# SF32LB55x register map
File version: 1.0
CPU: CM33 r0p1, little endian, MPU, FPU, 3 interrupt priority bits
Registers are 32-bit, read-write, reset 0x0 unless marked. A register's access mark holds for its fields unless they carry their own. Offsets are from the block's base; [hi:lo] are bit positions; {n}, {i} and the like mark numbered series.

## PMUC
Base 0x4007A000
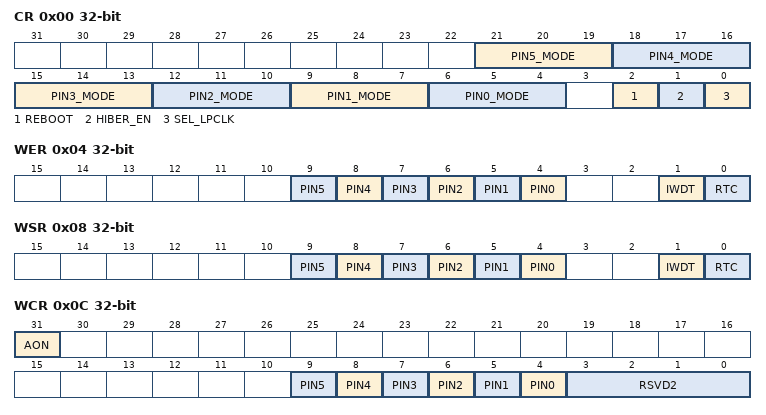
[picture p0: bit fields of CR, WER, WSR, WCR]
0x00 CR — Control Register
  [3n+6:3n+4] PIN{n}_MODE (n=1..5)
  [6:4] PIN0_MODE — 0 - high level, 1 - low level, 2 - pos edge, 3 - neg edge, 4/5/6/7: pos or neg edge
  [2] REBOOT — Write 1 to reboot; write 0 to clear after boot up
  [1] HIBER_EN — Write 1 to enter hibernate mode; write 0 to clear when exit from hibernate
  [0] SEL_LPCLK — 0 - LRC10, 1 - LXT32
0x04 WER — Wakeup Enable register
  [n+4] PIN{n} (n=0..5)
  [1] IWDT — Set 1 to enable IWDT as wakeup source
  [0] RTC — Set 1 to enable RTC as wakeup source
0x08 WSR — Wakeup Status register
  [n+4] PIN{n} (n=0..5)
  [1] IWDT — Indicates the wakeup status from LPTIM2. Note: the status is masked by WER
  [0] RTC — Indicates the wakeup status from RTC. Note: the status is masked by WER
0x0C WCR — Wakeup Clear register
  [31] AON — Write 1 to clear the AON wakeup IRQ status
  [n+4] PIN{n} (n=1..5)
  [4] PIN0 — Write 1 to clear the PIN0 wakeup source. Only valid if PIN wakeup is configured as edge trigger
  [3:0] RSVD2 — Note: for LPTIM and LPUART, clear the wakeup status directly in the orignal module
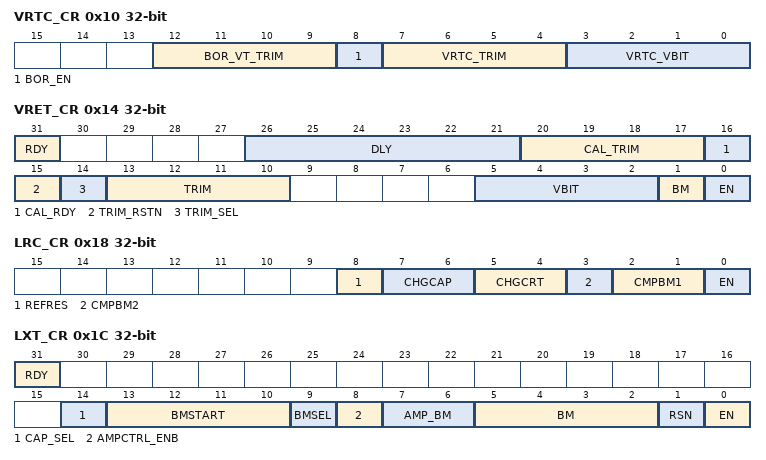
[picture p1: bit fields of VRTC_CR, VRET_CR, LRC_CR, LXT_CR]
0x10 VRTC_CR — VRTC Control Register
  [12:9] BOR_VT_TRIM
  [8] BOR_EN — Brownout Reset Enable
  [7:4] VRTC_TRIM
  [3:0] VRTC_VBIT
0x14 VRET_CR — VRET Control Register
  [31] RDY
  [26:21] DLY — VRET_LDO power up delay in number of CLK_LP cycles
  [20:17] CAL_TRIM
  [16] CAL_RDY
  [15] TRIM_RSTN
  [14] TRIM_SEL
  [13:10] TRIM
  [5:2] VBIT
  [1] BM
  [0] EN
0x18 LRC_CR — RC10K Control Register
  [8] REFRES
  [7:6] CHGCAP
  [5:4] CHGCRT
  [3] CMPBM2
  [2:1] CMPBM1
  [0] EN — Enabled by default
0x1C LXT_CR — XTAL32K Control Register
  [31] RDY, [14] CAP_SEL, [13:10] BMSTART, [9] BMSEL, [8] AMPCTRL_ENB, [7:6] AMP_BM, [5:2] BM, [1] RSN, [0] EN
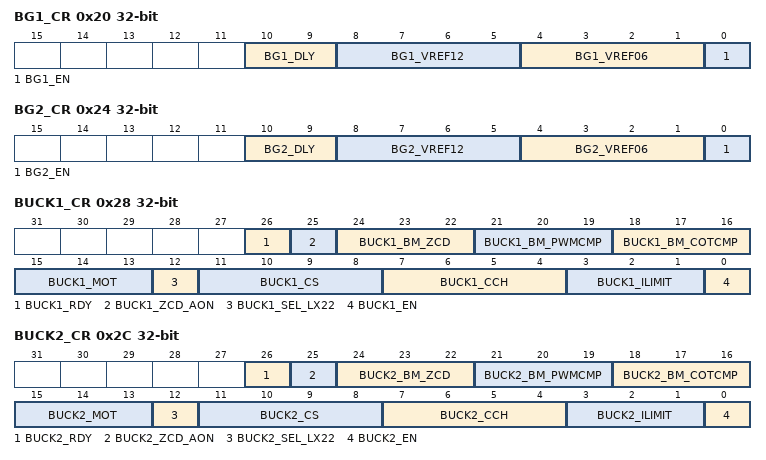
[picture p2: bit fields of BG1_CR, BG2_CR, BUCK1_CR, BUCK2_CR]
0x20 BG1_CR — BG1 Control Register
  [10:9] BG1_DLY — Bandgap power up delay in CLK_LP cycles
  [8:5] BG1_VREF12
  [4:1] BG1_VREF06
  [0] BG1_EN — Force BG1 enable
0x24 BG2_CR — BG2 Control Register
  [10:9] BG2_DLY — Bandgap power up delay in CLK_LP cycles
  [8:5] BG2_VREF12
  [4:1] BG2_VREF06
  [0] BG2_EN — Force BG2 enable
0x28 BUCK1_CR — BUCK1 Control Register 1
  [26] BUCK1_RDY, [25] BUCK1_ZCD_AON, [24:22] BUCK1_BM_ZCD, [21:19] BUCK1_BM_PWMCMP, [18:16] BUCK1_BM_COTCMP, [15:13] BUCK1_MOT, [12] BUCK1_SEL_LX22, [11:8] BUCK1_CS, [7:4] BUCK1_CCH, [3:1] BUCK1_ILIMIT, [0] BUCK1_EN
0x2C BUCK2_CR — BUCK2 Control Register 1
  [26] BUCK2_RDY, [25] BUCK2_ZCD_AON, [24:22] BUCK2_BM_ZCD, [21:19] BUCK2_BM_PWMCMP, [18:16] BUCK2_BM_COTCMP, [15:13] BUCK2_MOT, [12] BUCK2_SEL_LX22, [11:8] BUCK2_CS, [7:4] BUCK2_CCH, [3:1] BUCK2_ILIMIT, [0] BUCK2_EN
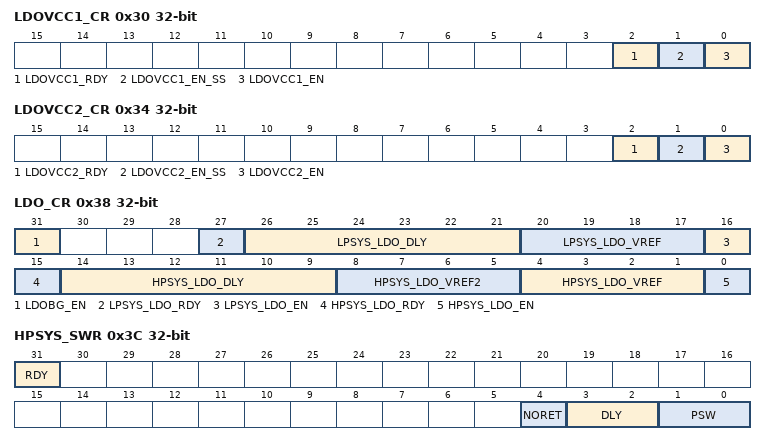
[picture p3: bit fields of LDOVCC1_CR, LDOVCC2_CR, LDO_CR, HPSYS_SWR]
0x30 LDOVCC1_CR — LDOVCC1 Control Register
  [2] LDOVCC1_RDY, [1] LDOVCC1_EN_SS, [0] LDOVCC1_EN
0x34 LDOVCC2_CR — LDOVCC2 Control Register
  [2] LDOVCC2_RDY, [1] LDOVCC2_EN_SS, [0] LDOVCC2_EN
0x38 LDO_CR — LDO Control Register
  [31] LDOBG_EN — Force LDOBG enable
  [27] LPSYS_LDO_RDY
  [26:21] LPSYS_LDO_DLY
  [20:17] LPSYS_LDO_VREF
  [16] LPSYS_LDO_EN
  [15] HPSYS_LDO_RDY
  [14:9] HPSYS_LDO_DLY — HPSYS_LDO power up delay in CLK_LP cycles
  [8:5] HPSYS_LDO_VREF2 — Lower voltage if needed, selected by HPSYS AON
  [4:1] HPSYS_LDO_VREF
  [0] HPSYS_LDO_EN
0x3C HPSYS_SWR — HPSYS Switch Register
  [31] RDY
  [4] NORET — Cut off power switch entirely during standby. No retention
  [3:2] DLY — wait for N cycles before asserting RDY
  [1:0] PSW — bit[0] - select RET_LDO; bit[1] - select HPSYS_LDO
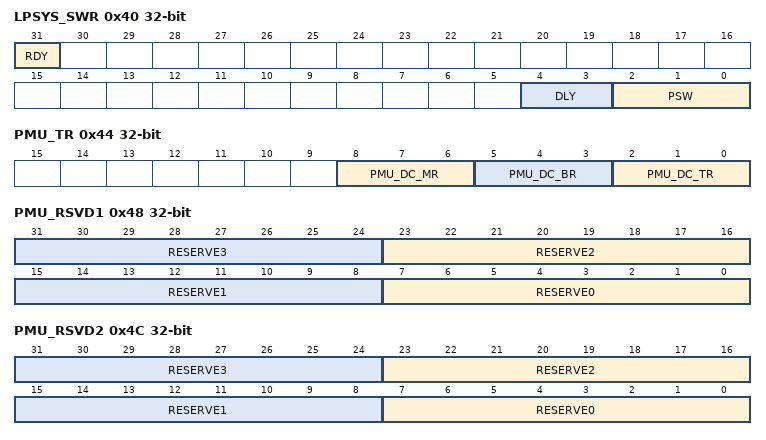
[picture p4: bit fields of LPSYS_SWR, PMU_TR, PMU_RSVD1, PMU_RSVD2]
0x40 LPSYS_SWR — LPSYS Switch Register
  [31] RDY
  [4:3] DLY
  [2:0] PSW — bit[0] - select RET_LDO; bit[1] - select BUCK2; bit [2] - select LPSYS_LDO
0x44 PMU_TR — PMU Test Register
  [8:6] PMU_DC_MR — macro select
  [5:3] PMU_DC_BR — block select
  [2:0] PMU_DC_TR — test point select
0x48 PMU_RSVD1 — PMU Reserved Register 1
  [8n+7:8n] RESERVE{n} (n=0..3)
0x4C PMU_RSVD2 — PMU Reserved Register 2
  [8n+7:8n] RESERVE{n} (n=0..3)
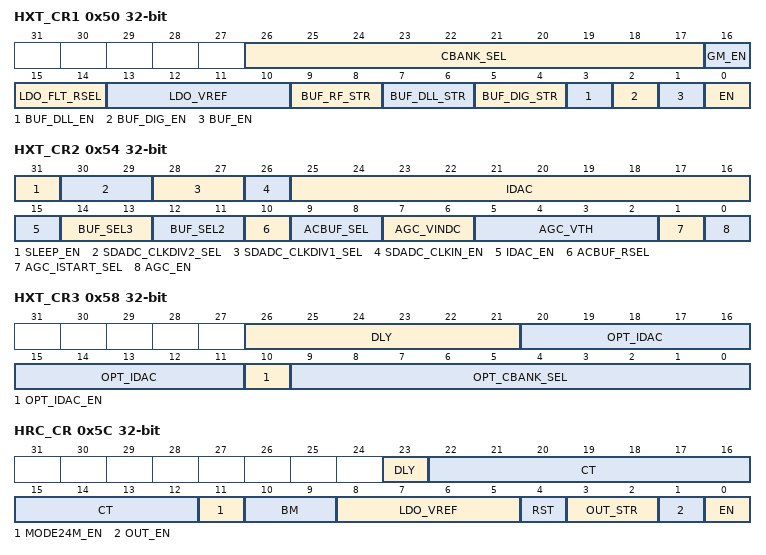
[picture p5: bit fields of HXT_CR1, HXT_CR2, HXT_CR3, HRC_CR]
0x50 HXT_CR1 — HXT48 Control Register 1
  [26:17] CBANK_SEL, [16] GM_EN, [15:14] LDO_FLT_RSEL, [13:10] LDO_VREF, [9:8] BUF_RF_STR, [7:6] BUF_DLL_STR, [5:4] BUF_DIG_STR, [3] BUF_DLL_EN, [2] BUF_DIG_EN, [1] BUF_EN, [0] EN
0x54 HXT_CR2 — HXT48 Control Register 2
  [31] SLEEP_EN, [30:29] SDADC_CLKDIV2_SEL, [28:27] SDADC_CLKDIV1_SEL, [26] SDADC_CLKIN_EN, [25:16] IDAC, [15] IDAC_EN, [14:13] BUF_SEL3, [12:11] BUF_SEL2, [10] ACBUF_RSEL, [9:8] ACBUF_SEL, [7:6] AGC_VINDC, [5:2] AGC_VTH, [1] AGC_ISTART_SEL, [0] AGC_EN
0x58 HXT_CR3 — HXT48 Control Register 3
  [26:21] DLY, [20:11] OPT_IDAC, [10] OPT_IDAC_EN, [9:0] OPT_CBANK_SEL
0x5C HRC_CR — HRC48 Control Register
  [23] DLY — number of cycles for BG ready. 0 - one cycle of CLK_LP; 1 - two cycles of CLK_LP
  [22:12] CT
  [11] MODE24M_EN
  [10:9] BM
  [8:5] LDO_VREF
  [4] RST
  [3:2] OUT_STR
  [1] OUT_EN
  [0] EN
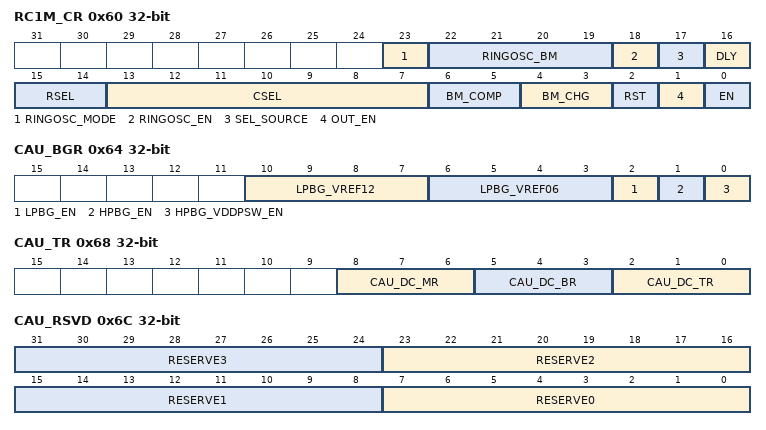
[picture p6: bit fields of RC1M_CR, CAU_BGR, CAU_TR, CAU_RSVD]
0x60 RC1M_CR — RC1M Control Register
  [23] RINGOSC_MODE
  [22:19] RINGOSC_BM
  [18] RINGOSC_EN
  [17] SEL_SOURCE
  [16] DLY — number of cycles for BG ready. 0 - one cycle of CLK_LP; 1 - two cycles of CLK_LP
  [15:14] RSEL
  [13:7] CSEL
  [6:5] BM_COMP
  [4:3] BM_CHG
  [2] RST
  [1] OUT_EN
  [0] EN
0x64 CAU_BGR — CAU Bandgap Register
  [10:7] LPBG_VREF12, [6:3] LPBG_VREF06, [2] LPBG_EN, [1] HPBG_EN, [0] HPBG_VDDPSW_EN
0x68 CAU_TR — CAU Test Register
  [8:6] CAU_DC_MR, [5:3] CAU_DC_BR, [2:0] CAU_DC_TR
0x6C CAU_RSVD — CAU Reserved Register
  [8n+7:8n] RESERVE{n} (n=0..3)
